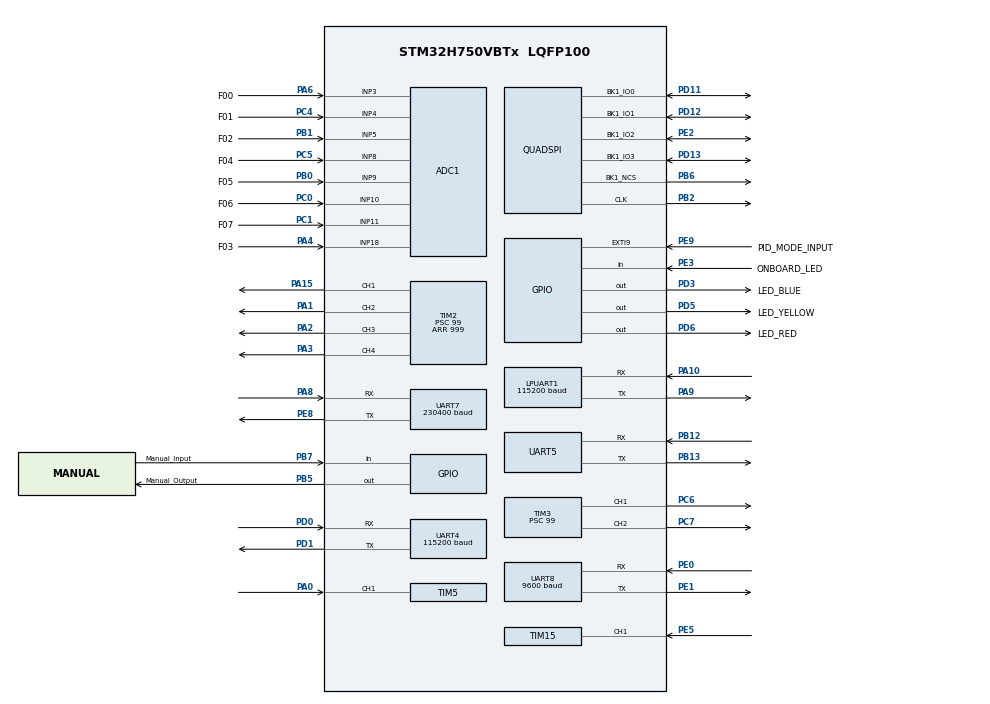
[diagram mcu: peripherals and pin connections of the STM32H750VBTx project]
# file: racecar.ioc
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ADC1.Channel-0\#ChannelRegularConversion=ADC_CHANNEL_3
ADC1.Channel-1\#ChannelRegularConversion=ADC_CHANNEL_4
ADC1.Channel-2\#ChannelRegularConversion=ADC_CHANNEL_5
ADC1.Channel-3\#ChannelRegularConversion=ADC_CHANNEL_8
ADC1.Channel-4\#ChannelRegularConversion=ADC_CHANNEL_9
ADC1.Channel-5\#ChannelRegularConversion=ADC_CHANNEL_10
ADC1.Channel-6\#ChannelRegularConversion=ADC_CHANNEL_11
ADC1.Channel-7\#ChannelRegularConversion=ADC_CHANNEL_18
ADC1.ClockPrescaler=ADC_CLOCK_ASYNC_DIV8
ADC1.ContinuousConvMode=ENABLE
ADC1.ConversionDataManagement=ADC_CONVERSIONDATA_DMA_CIRCULAR
ADC1.NbrOfConversion=8
ADC1.NbrOfConversionFlag=1
ADC1.OffsetNumber-0\#ChannelRegularConversion=ADC_OFFSET_NONE
ADC1.OffsetNumber-1\#ChannelRegularConversion=ADC_OFFSET_NONE
ADC1.OffsetNumber-2\#ChannelRegularConversion=ADC_OFFSET_NONE
ADC1.OffsetNumber-3\#ChannelRegularConversion=ADC_OFFSET_NONE
ADC1.OffsetNumber-4\#ChannelRegularConversion=ADC_OFFSET_NONE
ADC1.OffsetNumber-5\#ChannelRegularConversion=ADC_OFFSET_NONE
ADC1.OffsetNumber-6\#ChannelRegularConversion=ADC_OFFSET_NONE
ADC1.OffsetNumber-7\#ChannelRegularConversion=ADC_OFFSET_NONE
ADC1.OffsetSignedSaturation-0\#ChannelRegularConversion=DISABLE
ADC1.OffsetSignedSaturation-1\#ChannelRegularConversion=DISABLE
ADC1.OffsetSignedSaturation-2\#ChannelRegularConversion=DISABLE
ADC1.OffsetSignedSaturation-3\#ChannelRegularConversion=DISABLE
ADC1.OffsetSignedSaturation-4\#ChannelRegularConversion=DISABLE
ADC1.OffsetSignedSaturation-5\#ChannelRegularConversion=DISABLE
ADC1.OffsetSignedSaturation-6\#ChannelRegularConversion=DISABLE
ADC1.OffsetSignedSaturation-7\#ChannelRegularConversion=DISABLE
ADC1.Rank-0\#ChannelRegularConversion=1
ADC1.Rank-1\#ChannelRegularConversion=2
ADC1.Rank-2\#ChannelRegularConversion=3
ADC1.Rank-3\#ChannelRegularConversion=4
ADC1.Rank-4\#ChannelRegularConversion=5
ADC1.Rank-5\#ChannelRegularConversion=6
ADC1.Rank-6\#ChannelRegularConversion=7
ADC1.Rank-7\#ChannelRegularConversion=8
ADC1.SamplingTime-0\#ChannelRegularConversion=ADC_SAMPLETIME_32CYCLES_5
ADC1.SamplingTime-1\#ChannelRegularConversion=ADC_SAMPLETIME_32CYCLES_5
ADC1.SamplingTime-2\#ChannelRegularConversion=ADC_SAMPLETIME_32CYCLES_5
ADC1.SamplingTime-3\#ChannelRegularConversion=ADC_SAMPLETIME_32CYCLES_5
ADC1.SamplingTime-4\#ChannelRegularConversion=ADC_SAMPLETIME_32CYCLES_5
ADC1.SamplingTime-5\#ChannelRegularConversion=ADC_SAMPLETIME_32CYCLES_5
ADC1.SamplingTime-6\#ChannelRegularConversion=ADC_SAMPLETIME_32CYCLES_5
ADC1.SamplingTime-7\#ChannelRegularConversion=ADC_SAMPLETIME_32CYCLES_5
ADC1.master=1
Dma.ADC1.1.Direction=DMA_PERIPH_TO_MEMORY
Dma.ADC1.1.EventEnable=DISABLE
Dma.ADC1.1.FIFOMode=DMA_FIFOMODE_DISABLE
Dma.ADC1.1.Instance=DMA1_Stream1
Dma.ADC1.1.MemDataAlignment=DMA_MDATAALIGN_WORD
Dma.ADC1.1.MemInc=DMA_MINC_ENABLE
Dma.ADC1.1.Mode=DMA_CIRCULAR
Dma.ADC1.1.PeriphDataAlignment=DMA_PDATAALIGN_WORD
Dma.ADC1.1.PeriphInc=DMA_PINC_DISABLE
Dma.ADC1.1.Polarity=HAL_DMAMUX_REQ_GEN_RISING
Dma.ADC1.1.Priority=DMA_PRIORITY_LOW
Dma.ADC1.1.RequestNumber=1
Dma.ADC1.1.SignalID=NONE
Dma.ADC1.1.SyncEnable=DISABLE
Dma.ADC1.1.SyncPolarity=HAL_DMAMUX_SYNC_NO_EVENT
Dma.ADC1.1.SyncRequestNumber=1
Dma.ADC1.1.SyncSignalID=NONE
Dma.Request0=UART8_RX
Dma.Request1=ADC1
Dma.Request2=UART7_RX
Dma.Request3=UART4_RX
Dma.Request4=UART4_TX
Dma.Request5=UART5_RX
Dma.UART4_RX.3.Direction=DMA_PERIPH_TO_MEMORY
Dma.UART4_RX.3.EventEnable=DISABLE
Dma.UART4_RX.3.FIFOMode=DMA_FIFOMODE_DISABLE
Dma.UART4_RX.3.Instance=DMA1_Stream3
Dma.UART4_RX.3.MemDataAlignment=DMA_MDATAALIGN_BYTE
Dma.UART4_RX.3.MemInc=DMA_MINC_ENABLE
Dma.UART4_RX.3.Mode=DMA_NORMAL
Dma.UART4_RX.3.PeriphDataAlignment=DMA_PDATAALIGN_BYTE
Dma.UART4_RX.3.PeriphInc=DMA_PINC_DISABLE
Dma.UART4_RX.3.Polarity=HAL_DMAMUX_REQ_GEN_RISING
Dma.UART4_RX.3.Priority=DMA_PRIORITY_VERY_HIGH
Dma.UART4_RX.3.RequestNumber=1
Dma.UART4_RX.3.SignalID=NONE
Dma.UART4_RX.3.SyncEnable=DISABLE
Dma.UART4_RX.3.SyncPolarity=HAL_DMAMUX_SYNC_NO_EVENT
Dma.UART4_RX.3.SyncRequestNumber=1
Dma.UART4_RX.3.SyncSignalID=NONE
Dma.UART4_TX.4.Direction=DMA_MEMORY_TO_PERIPH
Dma.UART4_TX.4.EventEnable=DISABLE
Dma.UART4_TX.4.FIFOMode=DMA_FIFOMODE_DISABLE
Dma.UART4_TX.4.Instance=DMA1_Stream4
Dma.UART4_TX.4.MemDataAlignment=DMA_MDATAALIGN_BYTE
Dma.UART4_TX.4.MemInc=DMA_MINC_ENABLE
Dma.UART4_TX.4.Mode=DMA_NORMAL
Dma.UART4_TX.4.PeriphDataAlignment=DMA_PDATAALIGN_BYTE
Dma.UART4_TX.4.PeriphInc=DMA_PINC_DISABLE
Dma.UART4_TX.4.Polarity=HAL_DMAMUX_REQ_GEN_RISING
Dma.UART4_TX.4.Priority=DMA_PRIORITY_VERY_HIGH
Dma.UART4_TX.4.RequestNumber=1
Dma.UART4_TX.4.SignalID=NONE
Dma.UART4_TX.4.SyncEnable=DISABLE
Dma.UART4_TX.4.SyncPolarity=HAL_DMAMUX_SYNC_NO_EVENT
Dma.UART4_TX.4.SyncRequestNumber=1
Dma.UART4_TX.4.SyncSignalID=NONE
Dma.UART5_RX.5.Direction=DMA_PERIPH_TO_MEMORY
Dma.UART5_RX.5.EventEnable=DISABLE
Dma.UART5_RX.5.FIFOMode=DMA_FIFOMODE_DISABLE
Dma.UART5_RX.5.Instance=DMA1_Stream5
Dma.UART5_RX.5.MemDataAlignment=DMA_MDATAALIGN_BYTE
Dma.UART5_RX.5.MemInc=DMA_MINC_ENABLE
Dma.UART5_RX.5.Mode=DMA_CIRCULAR
Dma.UART5_RX.5.PeriphDataAlignment=DMA_PDATAALIGN_BYTE
Dma.UART5_RX.5.PeriphInc=DMA_PINC_DISABLE
Dma.UART5_RX.5.Polarity=HAL_DMAMUX_REQ_GEN_RISING
Dma.UART5_RX.5.Priority=DMA_PRIORITY_LOW
Dma.UART5_RX.5.RequestNumber=1
Dma.UART5_RX.5.SignalID=NONE
Dma.UART5_RX.5.SyncEnable=DISABLE
Dma.UART5_RX.5.SyncPolarity=HAL_DMAMUX_SYNC_NO_EVENT
Dma.UART5_RX.5.SyncRequestNumber=1
Dma.UART5_RX.5.SyncSignalID=NONE
Dma.UART7_RX.2.Direction=DMA_PERIPH_TO_MEMORY
Dma.UART7_RX.2.EventEnable=DISABLE
Dma.UART7_RX.2.FIFOMode=DMA_FIFOMODE_DISABLE
Dma.UART7_RX.2.Instance=DMA1_Stream2
Dma.UART7_RX.2.MemDataAlignment=DMA_MDATAALIGN_BYTE
Dma.UART7_RX.2.MemInc=DMA_MINC_ENABLE
Dma.UART7_RX.2.Mode=DMA_NORMAL
Dma.UART7_RX.2.PeriphDataAlignment=DMA_PDATAALIGN_BYTE
Dma.UART7_RX.2.PeriphInc=DMA_PINC_DISABLE
Dma.UART7_RX.2.Polarity=HAL_DMAMUX_REQ_GEN_RISING
Dma.UART7_RX.2.Priority=DMA_PRIORITY_LOW
Dma.UART7_RX.2.RequestNumber=1
Dma.UART7_RX.2.SignalID=NONE
Dma.UART7_RX.2.SyncEnable=DISABLE
Dma.UART7_RX.2.SyncPolarity=HAL_DMAMUX_SYNC_NO_EVENT
Dma.UART7_RX.2.SyncRequestNumber=1
Dma.UART7_RX.2.SyncSignalID=NONE
Dma.UART8_RX.0.Direction=DMA_PERIPH_TO_MEMORY
Dma.UART8_RX.0.EventEnable=DISABLE
Dma.UART8_RX.0.FIFOMode=DMA_FIFOMODE_DISABLE
Dma.UART8_RX.0.Instance=DMA1_Stream0
Dma.UART8_RX.0.MemDataAlignment=DMA_MDATAALIGN_BYTE
Dma.UART8_RX.0.MemInc=DMA_MINC_ENABLE
Dma.UART8_RX.0.Mode=DMA_NORMAL
Dma.UART8_RX.0.PeriphDataAlignment=DMA_PDATAALIGN_BYTE
Dma.UART8_RX.0.PeriphInc=DMA_PINC_DISABLE
Dma.UART8_RX.0.Polarity=HAL_DMAMUX_REQ_GEN_RISING
Dma.UART8_RX.0.Priority=DMA_PRIORITY_LOW
Dma.UART8_RX.0.RequestNumber=1
Dma.UART8_RX.0.SignalID=NONE
Dma.UART8_RX.0.SyncEnable=DISABLE
Dma.UART8_RX.0.SyncPolarity=HAL_DMAMUX_SYNC_NO_EVENT
Dma.UART8_RX.0.SyncRequestNumber=1
Dma.UART8_RX.0.SyncSignalID=NONE
LPUART1.BaudRate=115200
LPUART1.OneBitSampling=UART_ONE_BIT_SAMPLE_DISABLE
Mcu.Family=STM32H7
Mcu.Name=STM32H750VBTx
Mcu.Package=LQFP100
NVIC.ADC_IRQn=true\:0\:0\:false\:false\:true\:true\:true\:true
NVIC.DMA1_Stream0_IRQn=true\:0\:0\:false\:false\:true\:false\:true\:true
NVIC.DMA1_Stream1_IRQn=true\:0\:0\:false\:false\:true\:false\:true\:true
NVIC.DMA1_Stream2_IRQn=true\:0\:0\:false\:false\:true\:false\:true\:true
NVIC.DMA1_Stream3_IRQn=true\:0\:0\:false\:false\:true\:false\:true\:true
NVIC.DMA1_Stream4_IRQn=true\:0\:0\:false\:false\:true\:false\:true\:true
NVIC.DMA1_Stream5_IRQn=true\:0\:0\:false\:false\:true\:false\:true\:true
NVIC.EXTI9_5_IRQn=true\:0\:0\:false\:false\:true\:true\:true\:true
NVIC.PriorityGroup=NVIC_PRIORITYGROUP_4
NVIC.TIM15_IRQn=true\:0\:0\:false\:false\:true\:true\:true\:true
NVIC.TIM16_IRQn=true\:0\:0\:false\:false\:true\:true\:true\:true
NVIC.TIM5_IRQn=true\:0\:0\:false\:false\:true\:true\:true\:true
NVIC.TIM6_DAC_IRQn=true\:0\:0\:false\:false\:true\:true\:true\:true
NVIC.UART4_IRQn=true\:0\:0\:false\:false\:true\:true\:true\:true
NVIC.UART5_IRQn=true\:0\:0\:false\:false\:true\:true\:true\:true
NVIC.UART7_IRQn=true\:0\:0\:false\:false\:true\:true\:true\:true
NVIC.UART8_IRQn=true\:0\:0\:false\:false\:true\:true\:true\:true
PA0.Signal=S_TIM5_CH1
PA1.Signal=S_TIM2_CH2
PA10.Mode=Asynchronous
PA10.Signal=LPUART1_RX
PA13\ (JTMS/SWDIO).Mode=Serial_Wire
PA13\ (JTMS/SWDIO).Signal=DEBUG_JTMS-SWDIO
PA14\ (JTCK/SWCLK).Mode=Serial_Wire
PA14\ (JTCK/SWCLK).Signal=DEBUG_JTCK-SWCLK
PA15\ (JTDI).Signal=S_TIM2_CH1_ETR
PA2.Signal=S_TIM2_CH3
PA3.Signal=S_TIM2_CH4
PA4.GPIO_Label=F03
PA4.Signal=ADCx_INP18
PA6.GPIO_Label=F00
PA6.Signal=ADCx_INP3
PA8.Mode=Asynchronous
PA8.Signal=UART7_RX
PA9.Mode=Asynchronous
PA9.Signal=LPUART1_TX
PB0.GPIO_Label=F05
PB0.Signal=ADCx_INP9
PB1.GPIO_Label=F02
PB1.Signal=ADCx_INP5
PB12.Mode=Asynchronous
PB12.Signal=UART5_RX
PB13.Mode=Asynchronous
PB13.Signal=UART5_TX
PB2.Mode=Single Bank 1
PB2.Signal=QUADSPI_CLK
PB5.GPIO_Label=Manual_Output
PB5.Signal=GPIO_Output
PB6.Mode=Single Bank 1
PB6.Signal=QUADSPI_BK1_NCS
PB7.GPIO_Label=Manual_Input
PB7.Signal=GPIO_Input
PC0.GPIO_Label=F06
PC0.Signal=ADCx_INP10
PC1.GPIO_Label=F07
PC1.Signal=ADCx_INP11
PC14-OSC32_IN\ (OSC32_IN).Mode=LSE-External-Oscillator
PC14-OSC32_IN\ (OSC32_IN).Signal=RCC_OSC32_IN
PC15-OSC32_OUT\ (OSC32_OUT).Mode=LSE-External-Oscillator
PC15-OSC32_OUT\ (OSC32_OUT).Signal=RCC_OSC32_OUT
PC4.GPIO_Label=F01
PC4.Signal=ADCx_INP4
PC5.GPIO_Label=F04
PC5.Signal=ADCx_INP8
PC6.Signal=S_TIM3_CH1
PC7.Signal=S_TIM3_CH2
PD0.Mode=Asynchronous
PD0.Signal=UART4_RX
PD1.Mode=Asynchronous
PD1.Signal=UART4_TX
PD11.Mode=Single Bank 1
PD11.Signal=QUADSPI_BK1_IO0
PD12.Mode=Single Bank 1
PD12.Signal=QUADSPI_BK1_IO1
PD13.Mode=Single Bank 1
PD13.Signal=QUADSPI_BK1_IO3
PD3.GPIO_Label=LED_BLUE
PD3.Signal=GPIO_Output
PD5.GPIO_Label=LED_YELLOW
PD5.Signal=GPIO_Output
PD6.GPIO_Label=LED_RED
PD6.Signal=GPIO_Output
PE0.Mode=Asynchronous
PE0.Signal=UART8_RX
PE1.Mode=Asynchronous
PE1.Signal=UART8_TX
PE2.Mode=Single Bank 1
PE2.Signal=QUADSPI_BK1_IO2
PE3.GPIO_Label=ONBOARD_LED
PE3.Signal=GPIO_Input
PE5.Signal=S_TIM15_CH1
PE8.Mode=Asynchronous
PE8.Signal=UART7_TX
PE9.GPIO_Label=PID_MODE_INPUT
PE9.GPIO_ModeDefaultEXTI=GPIO_MODE_IT_RISING_FALLING
PE9.Signal=GPXTI9
PH0-OSC_IN\ (PH0).Mode=HSE-External-Oscillator
PH0-OSC_IN\ (PH0).Signal=RCC_OSC_IN
PH1-OSC_OUT\ (PH1).Mode=HSE-External-Oscillator
PH1-OSC_OUT\ (PH1).Signal=RCC_OSC_OUT
ProjectManager.HeapSize=0x200
ProjectManager.StackSize=0x400
ProjectManager.TargetToolchain=STM32CubeIDE
QUADSPI.ChipSelectHighTime=QSPI_CS_HIGH_TIME_5_CYCLE
QUADSPI.ClockPrescaler=10
QUADSPI.FlashSize=22
QUADSPI.SampleShifting=QSPI_SAMPLE_SHIFTING_HALFCYCLE
RCC.ADCCLockSelection=RCC_ADCCLKSOURCE_PLL3
RCC.ADCFreq_Value=40000000
RCC.APB1Freq_Value=50000000
RCC.APB2Freq_Value=50000000
RCC.APB3Freq_Value=50000000
RCC.APB4Freq_Value=50000000
RCC.CortexFreq_Value=400000000
RCC.D1PPRE=RCC_APB3_DIV4
RCC.D2PPRE1=RCC_APB1_DIV4
RCC.D2PPRE2=RCC_APB2_DIV4
RCC.D3PPRE=RCC_APB4_DIV4
RCC.DIVM1=5
RCC.DIVM2=10
RCC.DIVM3=10
RCC.DIVN1=160
RCC.DIVN2=60
RCC.DIVN3=128
RCC.DIVQ2=4
RCC.DIVR3=8
RCC.HCLKFreq_Value=200000000
RCC.HPRE=RCC_HCLK_DIV2
RCC.PLLSourceVirtual=RCC_PLLSOURCE_HSE
RCC.SYSCLKFreq_VALUE=400000000
RCC.SYSCLKSource=RCC_SYSCLKSOURCE_PLLCLK
RCC.USBFreq_Value=400000000
SH.ADCx_INP10.0=ADC1_INP10,IN10-Single-Ended
SH.ADCx_INP11.0=ADC1_INP11,IN11-Single-Ended
SH.ADCx_INP18.0=ADC1_INP18,IN18-Single-Ended
SH.ADCx_INP3.0=ADC1_INP3,IN3-Single-Ended
SH.ADCx_INP4.0=ADC1_INP4,IN4-Single-Ended
SH.ADCx_INP5.0=ADC1_INP5,IN5-Single-Ended
SH.ADCx_INP8.0=ADC1_INP8,IN8-Single-Ended
SH.ADCx_INP9.0=ADC1_INP9,IN9-Single-Ended
SH.S_TIM15_CH1.0=TIM15_CH1,PWM_Input_1
SH.S_TIM2_CH1_ETR.0=TIM2_CH1,PWM Generation1 CH1
SH.S_TIM2_CH2.0=TIM2_CH2,PWM Generation2 CH2
SH.S_TIM2_CH3.0=TIM2_CH3,PWM Generation3 CH3
SH.S_TIM2_CH4.0=TIM2_CH4,PWM Generation4 CH4
SH.S_TIM3_CH1.0=TIM3_CH1,PWM Generation1 CH1
SH.S_TIM3_CH2.0=TIM3_CH2,PWM Generation2 CH2
SH.S_TIM5_CH1.0=TIM5_CH1,PWM_Input_1
TIM15.AutoReloadPreload=TIM_AUTORELOAD_PRELOAD_ENABLE
TIM15.Prescaler=99
TIM16.AutoReloadPreload=TIM_AUTORELOAD_PRELOAD_ENABLE
TIM16.Prescaler=9999
TIM2.AutoReloadPreload=TIM_AUTORELOAD_PRELOAD_ENABLE
TIM2.Channel-PWM\ Generation1\ CH1=TIM_CHANNEL_1
TIM2.Channel-PWM\ Generation2\ CH2=TIM_CHANNEL_2
TIM2.Channel-PWM\ Generation3\ CH3=TIM_CHANNEL_3
TIM2.Channel-PWM\ Generation4\ CH4=TIM_CHANNEL_4
TIM2.Period=999
TIM2.Prescaler=99
TIM3.AutoReloadPreload=TIM_AUTORELOAD_PRELOAD_ENABLE
TIM3.Channel-PWM\ Generation1\ CH1=TIM_CHANNEL_1
TIM3.Channel-PWM\ Generation2\ CH2=TIM_CHANNEL_2
TIM3.Prescaler=99
TIM5.AutoReloadPreload=TIM_AUTORELOAD_PRELOAD_ENABLE
TIM5.Prescaler=99
TIM6.Prescaler=9999
UART4.BaudRate=115200
UART7.BaudRate=230400
UART8.BaudRate=9600
VP_TIM15_VS_ClockSourceINT.Mode=Internal
VP_TIM16_VS_ClockSourceINT.Mode=Enable_Timer
VP_TIM2_VS_ClockSourceINT.Mode=Internal
VP_TIM3_VS_ClockSourceINT.Mode=Internal
VP_TIM5_VS_ClockSourceINT.Mode=Internal
VP_TIM6_VS_ClockSourceINT.Mode=Enable_Timer
board=custom

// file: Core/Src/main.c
/* USER CODE BEGIN Header */
/**
  ******************************************************************************
  * @file           : main.c
  * @brief          : Main program body
  ******************************************************************************
  * @attention
  *
  * Copyright (c) 2024 STMicroelectronics.
  * All rights reserved.
  *
  * This software is licensed under terms that can be found in the LICENSE file
  * in the root directory of this software component.
  * If no LICENSE file comes with this software, it is provided AS-IS.
  *
  ******************************************************************************
  */
/* USER CODE END Header */
#include "main.h"

ADC_HandleTypeDef hadc1;
DMA_HandleTypeDef hdma_adc1;

UART_HandleTypeDef hlpuart1;
UART_HandleTypeDef huart4;
UART_HandleTypeDef huart5;
UART_HandleTypeDef huart7;
UART_HandleTypeDef huart8;
DMA_HandleTypeDef hdma_uart4_rx;
DMA_HandleTypeDef hdma_uart4_tx;
DMA_HandleTypeDef hdma_uart5_rx;
DMA_HandleTypeDef hdma_uart7_rx;
DMA_HandleTypeDef hdma_uart8_rx;

QSPI_HandleTypeDef hqspi;

TIM_HandleTypeDef htim2;
TIM_HandleTypeDef htim3;
TIM_HandleTypeDef htim5;
TIM_HandleTypeDef htim6;
TIM_HandleTypeDef htim15;
TIM_HandleTypeDef htim16;

void SystemClock_Config(void);
static void MX_GPIO_Init(void);
static void MX_DMA_Init(void);
static void MX_UART8_Init(void);
static void MX_UART4_Init(void);
static void MX_QUADSPI_Init(void);
static void MX_ADC1_Init(void);
static void MX_UART5_Init(void);
static void MX_UART7_Init(void);
static void MX_LPUART1_UART_Init(void);
static void MX_TIM2_Init(void);
static void MX_TIM16_Init(void);
static void MX_TIM3_Init(void);
static void MX_TIM5_Init(void);
static void MX_TIM15_Init(void);
static void MX_TIM6_Init(void);
/* USER CODE BEGIN PFP */
#ifdef __GNUC__
#define PUTCHAR_PROTOTYPE int __io_putchar(int ch)
#else
#define PUTCHAR_PROTOTYPE int fputc(int ch, FILE *f)
#endif

/* USER CODE END PFP */

/* USER CODE BEGIN 0 */
PUTCHAR_PROTOTYPE
{
  HAL_UART_Transmit(&huart7, (uint8_t *)&ch, 1, HAL_MAX_DELAY);
  return ch;
}

/* USER CODE END 0 */

int main(void)
{

  /* MCU Configuration--------------------------------------------------------*/

  /* Reset of all peripherals, Initializes the Flash interface and the Systick. */
  HAL_Init();

  /* Configure the system clock */
  SystemClock_Config();

  /* Initialize all configured peripherals */
  MX_GPIO_Init();
  MX_DMA_Init();
  MX_UART8_Init();
  MX_UART4_Init();
  MX_QUADSPI_Init();
  MX_ADC1_Init();
  MX_UART5_Init();
  MX_UART7_Init();
  MX_LPUART1_UART_Init();
  MX_TIM2_Init();
  MX_TIM16_Init();
  MX_TIM3_Init();
  MX_TIM5_Init();
  MX_TIM15_Init();
  MX_TIM6_Init();
  /* USER CODE BEGIN 2 */

  setup();
  /* USER CODE END 2 */

  /* Infinite loop */
  /* USER CODE BEGIN WHILE */
  while (1)
  {

	  loop();
    /* USER CODE END WHILE */

  }
}

void SystemClock_Config(void)
{
  RCC_OscInitTypeDef RCC_OscInitStruct = {0};
  RCC_ClkInitTypeDef RCC_ClkInitStruct = {0};

  /** Supply configuration update enable
  */
  HAL_PWREx_ConfigSupply(PWR_LDO_SUPPLY);

  /** Configure the main internal regulator output voltage
  */
  __HAL_PWR_VOLTAGESCALING_CONFIG(PWR_REGULATOR_VOLTAGE_SCALE1);

  while(!__HAL_PWR_GET_FLAG(PWR_FLAG_VOSRDY)) {}

  /** Initializes the RCC Oscillators according to the specified parameters
  * in the RCC_OscInitTypeDef structure.
  */
  RCC_OscInitStruct.OscillatorType = RCC_OSCILLATORTYPE_HSE;
  RCC_OscInitStruct.HSEState = RCC_HSE_ON;
  RCC_OscInitStruct.PLL.PLLState = RCC_PLL_ON;
  RCC_OscInitStruct.PLL.PLLSource = RCC_PLLSOURCE_HSE;
  RCC_OscInitStruct.PLL.PLLM = 5;
  RCC_OscInitStruct.PLL.PLLN = 160;
  RCC_OscInitStruct.PLL.PLLP = 2;
  RCC_OscInitStruct.PLL.PLLQ = 2;
  RCC_OscInitStruct.PLL.PLLR = 2;
  RCC_OscInitStruct.PLL.PLLRGE = RCC_PLL1VCIRANGE_2;
  RCC_OscInitStruct.PLL.PLLVCOSEL = RCC_PLL1VCOWIDE;
  RCC_OscInitStruct.PLL.PLLFRACN = 0;
  if (HAL_RCC_OscConfig(&RCC_OscInitStruct) != HAL_OK)
  {
    Error_Handler();
  }

  /** Initializes the CPU, AHB and APB buses clocks
  */
  RCC_ClkInitStruct.ClockType = RCC_CLOCKTYPE_HCLK|RCC_CLOCKTYPE_SYSCLK
                              |RCC_CLOCKTYPE_PCLK1|RCC_CLOCKTYPE_PCLK2
                              |RCC_CLOCKTYPE_D3PCLK1|RCC_CLOCKTYPE_D1PCLK1;
  RCC_ClkInitStruct.SYSCLKSource = RCC_SYSCLKSOURCE_PLLCLK;
  RCC_ClkInitStruct.SYSCLKDivider = RCC_SYSCLK_DIV1;
  RCC_ClkInitStruct.AHBCLKDivider = RCC_HCLK_DIV2;
  RCC_ClkInitStruct.APB3CLKDivider = RCC_APB3_DIV4;
  RCC_ClkInitStruct.APB1CLKDivider = RCC_APB1_DIV4;
  RCC_ClkInitStruct.APB2CLKDivider = RCC_APB2_DIV4;
  RCC_ClkInitStruct.APB4CLKDivider = RCC_APB4_DIV4;

  if (HAL_RCC_ClockConfig(&RCC_ClkInitStruct, FLASH_LATENCY_2) != HAL_OK)
  {
    Error_Handler();
  }
}

static void MX_ADC1_Init(void)
{

  ADC_MultiModeTypeDef multimode = {0};
  ADC_ChannelConfTypeDef sConfig = {0};

  /** Common config
  */
  hadc1.Instance = ADC1;
  hadc1.Init.ClockPrescaler = ADC_CLOCK_ASYNC_DIV8;
  hadc1.Init.Resolution = ADC_RESOLUTION_16B;
  hadc1.Init.ScanConvMode = ADC_SCAN_ENABLE;
  hadc1.Init.EOCSelection = ADC_EOC_SINGLE_CONV;
  hadc1.Init.LowPowerAutoWait = DISABLE;
  hadc1.Init.ContinuousConvMode = ENABLE;
  hadc1.Init.NbrOfConversion = 8;
  hadc1.Init.DiscontinuousConvMode = DISABLE;
  hadc1.Init.ExternalTrigConv = ADC_SOFTWARE_START;
  hadc1.Init.ExternalTrigConvEdge = ADC_EXTERNALTRIGCONVEDGE_NONE;
  hadc1.Init.ConversionDataManagement = ADC_CONVERSIONDATA_DMA_CIRCULAR;
  hadc1.Init.Overrun = ADC_OVR_DATA_PRESERVED;
  hadc1.Init.LeftBitShift = ADC_LEFTBITSHIFT_NONE;
  hadc1.Init.OversamplingMode = DISABLE;
  if (HAL_ADC_Init(&hadc1) != HAL_OK)
  {
    Error_Handler();
  }

  /** Configure the ADC multi-mode
  */
  multimode.Mode = ADC_MODE_INDEPENDENT;
  if (HAL_ADCEx_MultiModeConfigChannel(&hadc1, &multimode) != HAL_OK)
  {
    Error_Handler();
  }

  /** Configure Regular Channel
  */
  sConfig.Channel = ADC_CHANNEL_3;
  sConfig.Rank = ADC_REGULAR_RANK_1;
  sConfig.SamplingTime = ADC_SAMPLETIME_32CYCLES_5;
  sConfig.SingleDiff = ADC_SINGLE_ENDED;
  sConfig.OffsetNumber = ADC_OFFSET_NONE;
  sConfig.Offset = 0;
  sConfig.OffsetSignedSaturation = DISABLE;
  if (HAL_ADC_ConfigChannel(&hadc1, &sConfig) != HAL_OK)
  {
    Error_Handler();
  }

  /** Configure Regular Channel
  */
  sConfig.Channel = ADC_CHANNEL_4;
  sConfig.Rank = ADC_REGULAR_RANK_2;
  if (HAL_ADC_ConfigChannel(&hadc1, &sConfig) != HAL_OK)
  {
    Error_Handler();
  }

  /** Configure Regular Channel
  */
  sConfig.Channel = ADC_CHANNEL_5;
  sConfig.Rank = ADC_REGULAR_RANK_3;
  if (HAL_ADC_ConfigChannel(&hadc1, &sConfig) != HAL_OK)
  {
    Error_Handler();
  }

  /** Configure Regular Channel
  */
  sConfig.Channel = ADC_CHANNEL_8;
  sConfig.Rank = ADC_REGULAR_RANK_4;
  if (HAL_ADC_ConfigChannel(&hadc1, &sConfig) != HAL_OK)
  {
    Error_Handler();
  }

  /** Configure Regular Channel
  */
  sConfig.Channel = ADC_CHANNEL_9;
  sConfig.Rank = ADC_REGULAR_RANK_5;
  if (HAL_ADC_ConfigChannel(&hadc1, &sConfig) != HAL_OK)
  {
    Error_Handler();
  }

  /** Configure Regular Channel
  */
  sConfig.Channel = ADC_CHANNEL_10;
  sConfig.Rank = ADC_REGULAR_RANK_6;
  if (HAL_ADC_ConfigChannel(&hadc1, &sConfig) != HAL_OK)
  {
    Error_Handler();
  }

  /** Configure Regular Channel
  */
  sConfig.Channel = ADC_CHANNEL_11;
  sConfig.Rank = ADC_REGULAR_RANK_7;
  if (HAL_ADC_ConfigChannel(&hadc1, &sConfig) != HAL_OK)
  {
    Error_Handler();
  }

  /** Configure Regular Channel
  */
  sConfig.Channel = ADC_CHANNEL_18;
  sConfig.Rank = ADC_REGULAR_RANK_8;
  if (HAL_ADC_ConfigChannel(&hadc1, &sConfig) != HAL_OK)
  {
    Error_Handler();
  }

}

static void MX_LPUART1_UART_Init(void)
{

  hlpuart1.Instance = LPUART1;
  hlpuart1.Init.BaudRate = 115200;
  hlpuart1.Init.WordLength = UART_WORDLENGTH_8B;
  hlpuart1.Init.StopBits = UART_STOPBITS_1;
  hlpuart1.Init.Parity = UART_PARITY_NONE;
  hlpuart1.Init.Mode = UART_MODE_TX_RX;
  hlpuart1.Init.HwFlowCtl = UART_HWCONTROL_NONE;
  hlpuart1.Init.OneBitSampling = UART_ONE_BIT_SAMPLE_DISABLE;
  hlpuart1.Init.ClockPrescaler = UART_PRESCALER_DIV1;
  hlpuart1.AdvancedInit.AdvFeatureInit = UART_ADVFEATURE_NO_INIT;
  hlpuart1.FifoMode = UART_FIFOMODE_DISABLE;
  if (HAL_UART_Init(&hlpuart1) != HAL_OK)
  {
    Error_Handler();
  }
  if (HAL_UARTEx_SetTxFifoThreshold(&hlpuart1, UART_TXFIFO_THRESHOLD_1_8) != HAL_OK)
  {
    Error_Handler();
  }
  if (HAL_UARTEx_SetRxFifoThreshold(&hlpuart1, UART_RXFIFO_THRESHOLD_1_8) != HAL_OK)
  {
    Error_Handler();
  }
  if (HAL_UARTEx_DisableFifoMode(&hlpuart1) != HAL_OK)
  {
    Error_Handler();
  }

}

static void MX_UART4_Init(void)
{

  huart4.Instance = UART4;
  huart4.Init.BaudRate = 115200;
  huart4.Init.WordLength = UART_WORDLENGTH_8B;
  huart4.Init.StopBits = UART_STOPBITS_1;
  huart4.Init.Parity = UART_PARITY_NONE;
  huart4.Init.Mode = UART_MODE_TX_RX;
  huart4.Init.HwFlowCtl = UART_HWCONTROL_NONE;
  huart4.Init.OverSampling = UART_OVERSAMPLING_16;
  huart4.Init.OneBitSampling = UART_ONE_BIT_SAMPLE_DISABLE;
  huart4.Init.ClockPrescaler = UART_PRESCALER_DIV1;
  huart4.AdvancedInit.AdvFeatureInit = UART_ADVFEATURE_NO_INIT;
  if (HAL_UART_Init(&huart4) != HAL_OK)
  {
    Error_Handler();
  }
  if (HAL_UARTEx_SetTxFifoThreshold(&huart4, UART_TXFIFO_THRESHOLD_1_8) != HAL_OK)
  {
    Error_Handler();
  }
  if (HAL_UARTEx_SetRxFifoThreshold(&huart4, UART_RXFIFO_THRESHOLD_1_8) != HAL_OK)
  {
    Error_Handler();
  }
  if (HAL_UARTEx_DisableFifoMode(&huart4) != HAL_OK)
  {
    Error_Handler();
  }

}

static void MX_UART5_Init(void)
{

  huart5.Instance = UART5;
  huart5.Init.BaudRate = 115200;
  huart5.Init.WordLength = UART_WORDLENGTH_8B;
  huart5.Init.StopBits = UART_STOPBITS_1;
  huart5.Init.Parity = UART_PARITY_NONE;
  huart5.Init.Mode = UART_MODE_TX_RX;
  huart5.Init.HwFlowCtl = UART_HWCONTROL_NONE;
  huart5.Init.OverSampling = UART_OVERSAMPLING_16;
  huart5.Init.OneBitSampling = UART_ONE_BIT_SAMPLE_DISABLE;
  huart5.Init.ClockPrescaler = UART_PRESCALER_DIV1;
  huart5.AdvancedInit.AdvFeatureInit = UART_ADVFEATURE_NO_INIT;
  if (HAL_UART_Init(&huart5) != HAL_OK)
  {
    Error_Handler();
  }
  if (HAL_UARTEx_SetTxFifoThreshold(&huart5, UART_TXFIFO_THRESHOLD_1_8) != HAL_OK)
  {
    Error_Handler();
  }
  if (HAL_UARTEx_SetRxFifoThreshold(&huart5, UART_RXFIFO_THRESHOLD_1_8) != HAL_OK)
  {
    Error_Handler();
  }
  if (HAL_UARTEx_DisableFifoMode(&huart5) != HAL_OK)
  {
    Error_Handler();
  }

}

static void MX_UART7_Init(void)
{

  huart7.Instance = UART7;
  huart7.Init.BaudRate = 230400;
  huart7.Init.WordLength = UART_WORDLENGTH_8B;
  huart7.Init.StopBits = UART_STOPBITS_1;
  huart7.Init.Parity = UART_PARITY_NONE;
  huart7.Init.Mode = UART_MODE_TX_RX;
  huart7.Init.HwFlowCtl = UART_HWCONTROL_NONE;
  huart7.Init.OverSampling = UART_OVERSAMPLING_16;
  huart7.Init.OneBitSampling = UART_ONE_BIT_SAMPLE_DISABLE;
  huart7.Init.ClockPrescaler = UART_PRESCALER_DIV1;
  huart7.AdvancedInit.AdvFeatureInit = UART_ADVFEATURE_NO_INIT;
  if (HAL_UART_Init(&huart7) != HAL_OK)
  {
    Error_Handler();
  }
  if (HAL_UARTEx_SetTxFifoThreshold(&huart7, UART_TXFIFO_THRESHOLD_1_8) != HAL_OK)
  {
    Error_Handler();
  }
  if (HAL_UARTEx_SetRxFifoThreshold(&huart7, UART_RXFIFO_THRESHOLD_1_8) != HAL_OK)
  {
    Error_Handler();
  }
  if (HAL_UARTEx_DisableFifoMode(&huart7) != HAL_OK)
  {
    Error_Handler();
  }

}

static void MX_UART8_Init(void)
{

  huart8.Instance = UART8;
  huart8.Init.BaudRate = 9600;
  huart8.Init.WordLength = UART_WORDLENGTH_8B;
  huart8.Init.StopBits = UART_STOPBITS_1;
  huart8.Init.Parity = UART_PARITY_NONE;
  huart8.Init.Mode = UART_MODE_TX_RX;
  huart8.Init.HwFlowCtl = UART_HWCONTROL_NONE;
  huart8.Init.OverSampling = UART_OVERSAMPLING_16;
  huart8.Init.OneBitSampling = UART_ONE_BIT_SAMPLE_DISABLE;
  huart8.Init.ClockPrescaler = UART_PRESCALER_DIV1;
  huart8.AdvancedInit.AdvFeatureInit = UART_ADVFEATURE_NO_INIT;
  if (HAL_UART_Init(&huart8) != HAL_OK)
  {
    Error_Handler();
  }
  if (HAL_UARTEx_SetTxFifoThreshold(&huart8, UART_TXFIFO_THRESHOLD_1_8) != HAL_OK)
  {
    Error_Handler();
  }
  if (HAL_UARTEx_SetRxFifoThreshold(&huart8, UART_RXFIFO_THRESHOLD_1_8) != HAL_OK)
  {
    Error_Handler();
  }
  if (HAL_UARTEx_DisableFifoMode(&huart8) != HAL_OK)
  {
    Error_Handler();
  }

}

static void MX_QUADSPI_Init(void)
{

  /* QUADSPI parameter configuration*/
  hqspi.Instance = QUADSPI;
  hqspi.Init.ClockPrescaler = 10;
  hqspi.Init.FifoThreshold = 1;
  hqspi.Init.SampleShifting = QSPI_SAMPLE_SHIFTING_HALFCYCLE;
  hqspi.Init.FlashSize = 22;
  hqspi.Init.ChipSelectHighTime = QSPI_CS_HIGH_TIME_5_CYCLE;
  hqspi.Init.ClockMode = QSPI_CLOCK_MODE_0;
  hqspi.Init.FlashID = QSPI_FLASH_ID_1;
  hqspi.Init.DualFlash = QSPI_DUALFLASH_DISABLE;
  if (HAL_QSPI_Init(&hqspi) != HAL_OK)
  {
    Error_Handler();
  }

}

static void MX_TIM2_Init(void)
{

  TIM_ClockConfigTypeDef sClockSourceConfig = {0};
  TIM_MasterConfigTypeDef sMasterConfig = {0};
  TIM_OC_InitTypeDef sConfigOC = {0};

  htim2.Instance = TIM2;
  htim2.Init.Prescaler = 99;
  htim2.Init.CounterMode = TIM_COUNTERMODE_UP;
  htim2.Init.Period = 999;
  htim2.Init.ClockDivision = TIM_CLOCKDIVISION_DIV1;
  htim2.Init.AutoReloadPreload = TIM_AUTORELOAD_PRELOAD_ENABLE;
  if (HAL_TIM_Base_Init(&htim2) != HAL_OK)
  {
    Error_Handler();
  }
  sClockSourceConfig.ClockSource = TIM_CLOCKSOURCE_INTERNAL;
  if (HAL_TIM_ConfigClockSource(&htim2, &sClockSourceConfig) != HAL_OK)
  {
    Error_Handler();
  }
  if (HAL_TIM_PWM_Init(&htim2) != HAL_OK)
  {
    Error_Handler();
  }
  sMasterConfig.MasterOutputTrigger = TIM_TRGO_RESET;
  sMasterConfig.MasterSlaveMode = TIM_MASTERSLAVEMODE_DISABLE;
  if (HAL_TIMEx_MasterConfigSynchronization(&htim2, &sMasterConfig) != HAL_OK)
  {
    Error_Handler();
  }
  sConfigOC.OCMode = TIM_OCMODE_PWM1;
  sConfigOC.Pulse = 0;
  sConfigOC.OCPolarity = TIM_OCPOLARITY_HIGH;
  sConfigOC.OCFastMode = TIM_OCFAST_DISABLE;
  if (HAL_TIM_PWM_ConfigChannel(&htim2, &sConfigOC, TIM_CHANNEL_1) != HAL_OK)
  {
    Error_Handler();
  }
  if (HAL_TIM_PWM_ConfigChannel(&htim2, &sConfigOC, TIM_CHANNEL_2) != HAL_OK)
  {
    Error_Handler();
  }
  if (HAL_TIM_PWM_ConfigChannel(&htim2, &sConfigOC, TIM_CHANNEL_3) != HAL_OK)
  {
    Error_Handler();
  }
  if (HAL_TIM_PWM_ConfigChannel(&htim2, &sConfigOC, TIM_CHANNEL_4) != HAL_OK)
  {
    Error_Handler();
  }
  HAL_TIM_MspPostInit(&htim2);

}

static void MX_TIM3_Init(void)
{

  TIM_ClockConfigTypeDef sClockSourceConfig = {0};
  TIM_MasterConfigTypeDef sMasterConfig = {0};
  TIM_OC_InitTypeDef sConfigOC = {0};

  htim3.Instance = TIM3;
  htim3.Init.Prescaler = 99;
  htim3.Init.CounterMode = TIM_COUNTERMODE_UP;
  htim3.Init.Period = 65535;
  htim3.Init.ClockDivision = TIM_CLOCKDIVISION_DIV1;
  htim3.Init.AutoReloadPreload = TIM_AUTORELOAD_PRELOAD_ENABLE;
  if (HAL_TIM_Base_Init(&htim3) != HAL_OK)
  {
    Error_Handler();
  }
  sClockSourceConfig.ClockSource = TIM_CLOCKSOURCE_INTERNAL;
  if (HAL_TIM_ConfigClockSource(&htim3, &sClockSourceConfig) != HAL_OK)
  {
    Error_Handler();
  }
  if (HAL_TIM_PWM_Init(&htim3) != HAL_OK)
  {
    Error_Handler();
  }
  sMasterConfig.MasterOutputTrigger = TIM_TRGO_RESET;
  sMasterConfig.MasterSlaveMode = TIM_MASTERSLAVEMODE_DISABLE;
  if (HAL_TIMEx_MasterConfigSynchronization(&htim3, &sMasterConfig) != HAL_OK)
  {
    Error_Handler();
  }
  sConfigOC.OCMode = TIM_OCMODE_PWM1;
  sConfigOC.Pulse = 0;
  sConfigOC.OCPolarity = TIM_OCPOLARITY_HIGH;
  sConfigOC.OCFastMode = TIM_OCFAST_DISABLE;
  if (HAL_TIM_PWM_ConfigChannel(&htim3, &sConfigOC, TIM_CHANNEL_1) != HAL_OK)
  {
    Error_Handler();
  }
  if (HAL_TIM_PWM_ConfigChannel(&htim3, &sConfigOC, TIM_CHANNEL_2) != HAL_OK)
  {
    Error_Handler();
  }
  HAL_TIM_MspPostInit(&htim3);

}

static void MX_TIM5_Init(void)
{

  TIM_ClockConfigTypeDef sClockSourceConfig = {0};
  TIM_SlaveConfigTypeDef sSlaveConfig = {0};
  TIM_IC_InitTypeDef sConfigIC = {0};
  TIM_MasterConfigTypeDef sMasterConfig = {0};

  htim5.Instance = TIM5;
  htim5.Init.Prescaler = 99;
  htim5.Init.CounterMode = TIM_COUNTERMODE_UP;
  htim5.Init.Period = 4294967295;
  htim5.Init.ClockDivision = TIM_CLOCKDIVISION_DIV1;
  htim5.Init.AutoReloadPreload = TIM_AUTORELOAD_PRELOAD_ENABLE;
  if (HAL_TIM_Base_Init(&htim5) != HAL_OK)
  {
    Error_Handler();
  }
  sClockSourceConfig.ClockSource = TIM_CLOCKSOURCE_INTERNAL;
  if (HAL_TIM_ConfigClockSource(&htim5, &sClockSourceConfig) != HAL_OK)
  {
    Error_Handler();
  }
  if (HAL_TIM_IC_Init(&htim5) != HAL_OK)
  {
    Error_Handler();
  }
  sSlaveConfig.SlaveMode = TIM_SLAVEMODE_RESET;
  sSlaveConfig.InputTrigger = TIM_TS_TI1FP1;
  sSlaveConfig.TriggerPolarity = TIM_INPUTCHANNELPOLARITY_RISING;
  sSlaveConfig.TriggerPrescaler = TIM_ICPSC_DIV1;
  sSlaveConfig.TriggerFilter = 0;
  if (HAL_TIM_SlaveConfigSynchro(&htim5, &sSlaveConfig) != HAL_OK)
  {
    Error_Handler();
  }
  sConfigIC.ICPolarity = TIM_INPUTCHANNELPOLARITY_RISING;
  sConfigIC.ICSelection = TIM_ICSELECTION_DIRECTTI;
  sConfigIC.ICPrescaler = TIM_ICPSC_DIV1;
  sConfigIC.ICFilter = 0;
  if (HAL_TIM_IC_ConfigChannel(&htim5, &sConfigIC, TIM_CHANNEL_1) != HAL_OK)
  {
    Error_Handler();
  }
  sConfigIC.ICPolarity = TIM_INPUTCHANNELPOLARITY_FALLING;
  sConfigIC.ICSelection = TIM_ICSELECTION_INDIRECTTI;
  if (HAL_TIM_IC_ConfigChannel(&htim5, &sConfigIC, TIM_CHANNEL_2) != HAL_OK)
  {
    Error_Handler();
  }
  sMasterConfig.MasterOutputTrigger = TIM_TRGO_RESET;
  sMasterConfig.MasterSlaveMode = TIM_MASTERSLAVEMODE_DISABLE;
  if (HAL_TIMEx_MasterConfigSynchronization(&htim5, &sMasterConfig) != HAL_OK)
  {
    Error_Handler();
  }

}

static void MX_TIM6_Init(void)
{

  TIM_MasterConfigTypeDef sMasterConfig = {0};

  htim6.Instance = TIM6;
  htim6.Init.Prescaler = 9999;
  htim6.Init.CounterMode = TIM_COUNTERMODE_UP;
  htim6.Init.Period = 65535;
  htim6.Init.AutoReloadPreload = TIM_AUTORELOAD_PRELOAD_DISABLE;
  if (HAL_TIM_Base_Init(&htim6) != HAL_OK)
  {
    Error_Handler();
  }
  sMasterConfig.MasterOutputTrigger = TIM_TRGO_RESET;
  sMasterConfig.MasterSlaveMode = TIM_MASTERSLAVEMODE_DISABLE;
  if (HAL_TIMEx_MasterConfigSynchronization(&htim6, &sMasterConfig) != HAL_OK)
  {
    Error_Handler();
  }

}

static void MX_TIM15_Init(void)
{

  TIM_ClockConfigTypeDef sClockSourceConfig = {0};
  TIM_SlaveConfigTypeDef sSlaveConfig = {0};
  TIM_IC_InitTypeDef sConfigIC = {0};
  TIM_MasterConfigTypeDef sMasterConfig = {0};

  htim15.Instance = TIM15;
  htim15.Init.Prescaler = 99;
  htim15.Init.CounterMode = TIM_COUNTERMODE_UP;
  htim15.Init.Period = 65535;
  htim15.Init.ClockDivision = TIM_CLOCKDIVISION_DIV1;
  htim15.Init.RepetitionCounter = 0;
  htim15.Init.AutoReloadPreload = TIM_AUTORELOAD_PRELOAD_ENABLE;
  if (HAL_TIM_Base_Init(&htim15) != HAL_OK)
  {
    Error_Handler();
  }
  sClockSourceConfig.ClockSource = TIM_CLOCKSOURCE_INTERNAL;
  if (HAL_TIM_ConfigClockSource(&htim15, &sClockSourceConfig) != HAL_OK)
  {
    Error_Handler();
  }
  if (HAL_TIM_IC_Init(&htim15) != HAL_OK)
  {
    Error_Handler();
  }
  sSlaveConfig.SlaveMode = TIM_SLAVEMODE_RESET;
  sSlaveConfig.InputTrigger = TIM_TS_TI1FP1;
  sSlaveConfig.TriggerPolarity = TIM_INPUTCHANNELPOLARITY_RISING;
  sSlaveConfig.TriggerPrescaler = TIM_ICPSC_DIV1;
  sSlaveConfig.TriggerFilter = 0;
  if (HAL_TIM_SlaveConfigSynchro(&htim15, &sSlaveConfig) != HAL_OK)
  {
    Error_Handler();
  }
  sConfigIC.ICPolarity = TIM_INPUTCHANNELPOLARITY_RISING;
  sConfigIC.ICSelection = TIM_ICSELECTION_DIRECTTI;
  sConfigIC.ICPrescaler = TIM_ICPSC_DIV1;
  sConfigIC.ICFilter = 0;
  if (HAL_TIM_IC_ConfigChannel(&htim15, &sConfigIC, TIM_CHANNEL_1) != HAL_OK)
  {
    Error_Handler();
  }
  sConfigIC.ICPolarity = TIM_INPUTCHANNELPOLARITY_FALLING;
  sConfigIC.ICSelection = TIM_ICSELECTION_INDIRECTTI;
  if (HAL_TIM_IC_ConfigChannel(&htim15, &sConfigIC, TIM_CHANNEL_2) != HAL_OK)
  {
    Error_Handler();
  }
  sMasterConfig.MasterOutputTrigger = TIM_TRGO_RESET;
  sMasterConfig.MasterSlaveMode = TIM_MASTERSLAVEMODE_DISABLE;
  if (HAL_TIMEx_MasterConfigSynchronization(&htim15, &sMasterConfig) != HAL_OK)
  {
    Error_Handler();
  }

}

static void MX_TIM16_Init(void)
{

  htim16.Instance = TIM16;
  htim16.Init.Prescaler = 9999;
  htim16.Init.CounterMode = TIM_COUNTERMODE_UP;
  htim16.Init.Period = 65535;
  htim16.Init.ClockDivision = TIM_CLOCKDIVISION_DIV1;
  htim16.Init.RepetitionCounter = 0;
  htim16.Init.AutoReloadPreload = TIM_AUTORELOAD_PRELOAD_ENABLE;
  if (HAL_TIM_Base_Init(&htim16) != HAL_OK)
  {
    Error_Handler();
  }

}

static void MX_DMA_Init(void)
{

  /* DMA controller clock enable */
  __HAL_RCC_DMA1_CLK_ENABLE();

  /* DMA interrupt init */
  /* DMA1_Stream0_IRQn interrupt configuration */
  HAL_NVIC_SetPriority(DMA1_Stream0_IRQn, 0, 0);
  HAL_NVIC_EnableIRQ(DMA1_Stream0_IRQn);
  /* DMA1_Stream1_IRQn interrupt configuration */
  HAL_NVIC_SetPriority(DMA1_Stream1_IRQn, 0, 0);
  HAL_NVIC_EnableIRQ(DMA1_Stream1_IRQn);
  /* DMA1_Stream2_IRQn interrupt configuration */
  HAL_NVIC_SetPriority(DMA1_Stream2_IRQn, 0, 0);
  HAL_NVIC_EnableIRQ(DMA1_Stream2_IRQn);
  /* DMA1_Stream3_IRQn interrupt configuration */
  HAL_NVIC_SetPriority(DMA1_Stream3_IRQn, 0, 0);
  HAL_NVIC_EnableIRQ(DMA1_Stream3_IRQn);
  /* DMA1_Stream4_IRQn interrupt configuration */
  HAL_NVIC_SetPriority(DMA1_Stream4_IRQn, 0, 0);
  HAL_NVIC_EnableIRQ(DMA1_Stream4_IRQn);
  /* DMA1_Stream5_IRQn interrupt configuration */
  HAL_NVIC_SetPriority(DMA1_Stream5_IRQn, 0, 0);
  HAL_NVIC_EnableIRQ(DMA1_Stream5_IRQn);

}

static void MX_GPIO_Init(void)
{
  GPIO_InitTypeDef GPIO_InitStruct = {0};

  /* GPIO Ports Clock Enable */
  __HAL_RCC_GPIOE_CLK_ENABLE();
  __HAL_RCC_GPIOC_CLK_ENABLE();
  __HAL_RCC_GPIOH_CLK_ENABLE();
  __HAL_RCC_GPIOA_CLK_ENABLE();
  __HAL_RCC_GPIOB_CLK_ENABLE();
  __HAL_RCC_GPIOD_CLK_ENABLE();

  /*Configure GPIO pin Output Level */
  HAL_GPIO_WritePin(GPIOD, LED_BLUE_Pin|LED_YELLOW_Pin|LED_RED_Pin, GPIO_PIN_RESET);

  /*Configure GPIO pin Output Level */
  HAL_GPIO_WritePin(Manual_Output_GPIO_Port, Manual_Output_Pin, GPIO_PIN_RESET);

  /*Configure GPIO pin : ONBOARD_LED_Pin */
  GPIO_InitStruct.Pin = ONBOARD_LED_Pin;
  GPIO_InitStruct.Mode = GPIO_MODE_INPUT;
  GPIO_InitStruct.Pull = GPIO_NOPULL;
  HAL_GPIO_Init(ONBOARD_LED_GPIO_Port, &GPIO_InitStruct);

  /*Configure GPIO pin : PID_MODE_INPUT_Pin */
  GPIO_InitStruct.Pin = PID_MODE_INPUT_Pin;
  GPIO_InitStruct.Mode = GPIO_MODE_IT_RISING_FALLING;
  GPIO_InitStruct.Pull = GPIO_NOPULL;
  HAL_GPIO_Init(PID_MODE_INPUT_GPIO_Port, &GPIO_InitStruct);

  /*Configure GPIO pins : LED_BLUE_Pin LED_YELLOW_Pin LED_RED_Pin */
  GPIO_InitStruct.Pin = LED_BLUE_Pin|LED_YELLOW_Pin|LED_RED_Pin;
  GPIO_InitStruct.Mode = GPIO_MODE_OUTPUT_PP;
  GPIO_InitStruct.Pull = GPIO_NOPULL;
  GPIO_InitStruct.Speed = GPIO_SPEED_FREQ_LOW;
  HAL_GPIO_Init(GPIOD, &GPIO_InitStruct);

  /*Configure GPIO pin : Manual_Output_Pin */
  GPIO_InitStruct.Pin = Manual_Output_Pin;
  GPIO_InitStruct.Mode = GPIO_MODE_OUTPUT_PP;
  GPIO_InitStruct.Pull = GPIO_NOPULL;
  GPIO_InitStruct.Speed = GPIO_SPEED_FREQ_LOW;
  HAL_GPIO_Init(Manual_Output_GPIO_Port, &GPIO_InitStruct);

  /*Configure GPIO pin : Manual_Input_Pin */
  GPIO_InitStruct.Pin = Manual_Input_Pin;
  GPIO_InitStruct.Mode = GPIO_MODE_INPUT;
  GPIO_InitStruct.Pull = GPIO_NOPULL;
  HAL_GPIO_Init(Manual_Input_GPIO_Port, &GPIO_InitStruct);

  /* EXTI interrupt init*/
  HAL_NVIC_SetPriority(EXTI9_5_IRQn, 0, 0);
  HAL_NVIC_EnableIRQ(EXTI9_5_IRQn);

}

void Error_Handler(void)
{
  __disable_irq();
  while (1)
  {
  }
}
